# ATmega162 register map
Vendor: Atmel; File version: 1.0
CPU: other r0p0, little endian, no MPU, no FPU, 4 interrupt priority bits
Registers are 8-bit, read-write, reset 0x0 unless marked. A register's access mark holds for its fields unless they carry their own. Offsets are from the block's base; [hi:lo] are bit positions.

## TC0 — Timer/Counter, 8-bit
Base 0x00800051
0x00 OCR0 — Timer/Counter 0 Output Compare Register
0x01 TCNT0 — Timer/Counter 0 Register
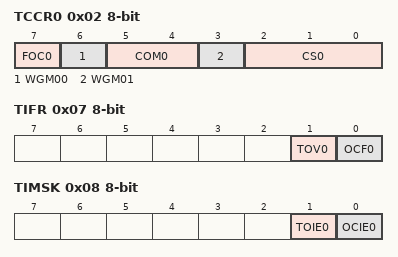
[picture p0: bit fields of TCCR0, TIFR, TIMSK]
0x02 TCCR0 — Timer/Counter 0 Control Register
  [7] FOC0 — Force Output Compare
  [6] WGM00 — Waveform Generation Mode 0
    0=NORMAL; 1=CTC
  [5:4] COM0 — Compare Match Output Modes
  [3] WGM01 — Waveform Generation Mode 1
  [2:0] CS0 — Clock Selects
    0=NO_CLOCK_SOURCE_STOPPED; 1=RUNNING_NO_PRESCALING; 2=RUNNING_CLK_8; 3=RUNNING_CLK_64; 4=RUNNING_CLK_256; 5=RUNNING_CLK_1024; 6=RUNNING_EXTCLK_TN_FALLING_EDGE; 7=RUNNING_EXTCLK_TN_RISING_EDGE
0x07 TIFR — Timer/Counter Interrupt Flag register (read-only for debugger)
  [1] TOV0 — Timer/Counter0 Overflow Flag
  [0] OCF0 — Output Compare Flag 0
0x08 TIMSK — Timer/Counter Interrupt Mask Register
  [1] TOIE0 — Timer/Counter0 Overflow Interrupt Enable
  [0] OCIE0 — Timer/Counter0 Output Compare Match Interrupt register

## TC1 — Timer/Counter, 16-bit
Base 0x00800044
0x00 ICR1 16-bit (reset mask 0xFF) — Timer/Counter1 Input Capture Register Bytes
0x04 OCR1B 16-bit (reset mask 0xFF) — Timer/Counter1 Output Compare Register B Bytes
0x06 OCR1A 16-bit (reset mask 0xFF) — Timer/Counter1 Output Compare Register A Bytes
0x08 TCNT1 16-bit (reset mask 0xFF) — Timer/Counter1 Bytes
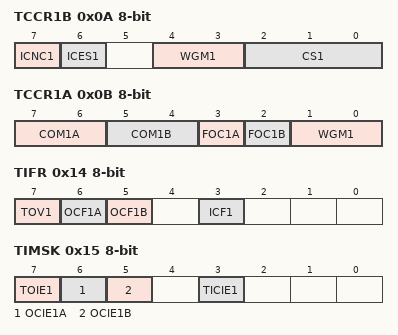
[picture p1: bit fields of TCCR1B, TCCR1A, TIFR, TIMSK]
0x0A TCCR1B — Timer/Counter1 Control Register B
  [7] ICNC1 — Input Capture 1 Noise Canceler
  [6] ICES1 — Input Capture 1 Edge Select
  [4:3] WGM1 — Pulse Width Modulator Select Bits
  [2:0] CS1 — Clock Select1 bits
    0=NO_CLOCK_SOURCE_STOPPED; 1=RUNNING_NO_PRESCALING; 2=RUNNING_CLK_8; 3=RUNNING_CLK_64; 4=RUNNING_CLK_256; 5=RUNNING_CLK_1024; 6=RUNNING_EXTCLK_TN_FALLING_EDGE; 7=RUNNING_EXTCLK_TN_RISING_EDGE
0x0B TCCR1A — Timer/Counter1 Control Register A
  [7:6] COM1A — Compare Output Mode 1A, bits
  [5:4] COM1B — Compare Output Mode 1B, bits
  [3] FOC1A — Force Output Compare for Channel A
  [2] FOC1B — Force Output Compare for Channel B
  [1:0] WGM1 — Pulse Width Modulator Select Bits
0x14 TIFR — Timer/Counter Interrupt Flag register (read-only for debugger)
  [7] TOV1 — Timer/Counter1 Overflow Flag
  [6] OCF1A — Output Compare Flag 1A
  [5] OCF1B — Output Compare Flag 1B
  [3] ICF1 — Input Capture Flag 1
0x15 TIMSK — Timer/Counter Interrupt Mask Register
  [7] TOIE1 — Timer/Counter1 Overflow Interrupt Enable
  [6] OCIE1A — Timer/Counter1 Output CompareA Match Interrupt Enable
  [5] OCIE1B — Timer/Counter1 Output CompareB Match Interrupt Enable
  [3] TICIE1 — Timer/Counter1 Input Capture Interrupt Enable

## TC2 — Timer/Counter, 8-bit Async
Base 0x00800042
0x00 OCR2 — Output Compare Register
0x01 TCNT2 — Timer/Counter Register
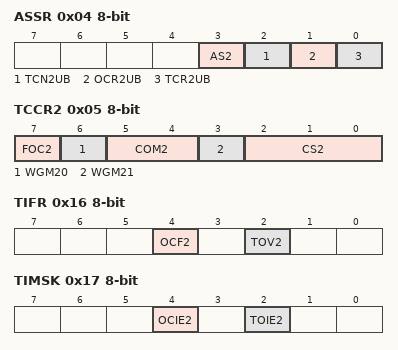
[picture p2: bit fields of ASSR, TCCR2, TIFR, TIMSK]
0x04 ASSR — Asynchronous Status Register
  [3] AS2 — Asynchronous Timer 2
  [2] TCN2UB — Timer/Counter2 Update Busy
  [1] OCR2UB — Output Compare Register2 Update Busy
  [0] TCR2UB — Timer/Counter Control Register2 Update Busy
0x05 TCCR2 — Timer/Counter Control Register
  [7] FOC2 — Force Output Compare
  [6] WGM20 — Pulse Width Modulator Select Bit 0
    0=NORMAL; 1=CTC
  [5:4] COM2 — Compare Match Output Mode
  [3] WGM21 — Pulse Width Modulator Select Bit 1
  [2:0] CS2 — Clock Select
    0=NO_CLOCK_SOURCE_STOPPED; 1=RUNNING_NO_PRESCALING; 2=RUNNING_CLK_8; 3=RUNNING_CLK_32; 4=RUNNING_CLK_64; 5=RUNNING_CLK_128; 6=RUNNING_CLK_256; 7=RUNNING_CLK_1024
0x16 TIFR — Timer/Counter Interrupt Flag Register (read-only for debugger)
  [4] OCF2 — Output Compare Flag 2
  [2] TOV2 — Timer/Counter2 Overflow Flag
0x17 TIMSK — Timer/Counter Interrupt Mask Register
  [4] OCIE2 — Timer/Counter2 Output Compare Match Interrupt Enable
  [2] TOIE2 — Timer/Counter2 Overflow Interrupt Enable
